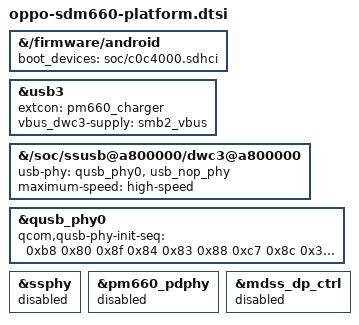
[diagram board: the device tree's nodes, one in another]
// SPDX-License-Identifier: GPL-2.0

&{/firmware/android} {
	boot_devices = "soc/c0c4000.sdhci";
	/delete-node/ vbmeta;
	/delete-node/ fstab;
};

&usb3 {
	extcon = <&pm660_charger>;
	vbus_dwc3-supply = <&smb2_vbus>;
};

&{/soc/ssusb@a800000/dwc3@a800000} {
	usb-phy = <&qusb_phy0>, <&usb_nop_phy>;
	maximum-speed = "high-speed";
	/delete-property/ snps,usb3_lpm_capable;
};

&qusb_phy0 {

	qcom,qusb-phy-init-seq = <0xb8 0x80
				    0x8f 0x84
				    0x83 0x88
				    0xc7 0x8c
				    0x30 0x08
				    0x79 0x0c
				    0x21 0x10
				    0x14 0x9c
				    0x9f 0x1c
				    0x00 0x18>;
};

&ssphy {
	status = "disabled";
};

&pm660_pdphy {

	status = "disabled";
};

&mdss_dp_ctrl {
	status = "disabled";
};
